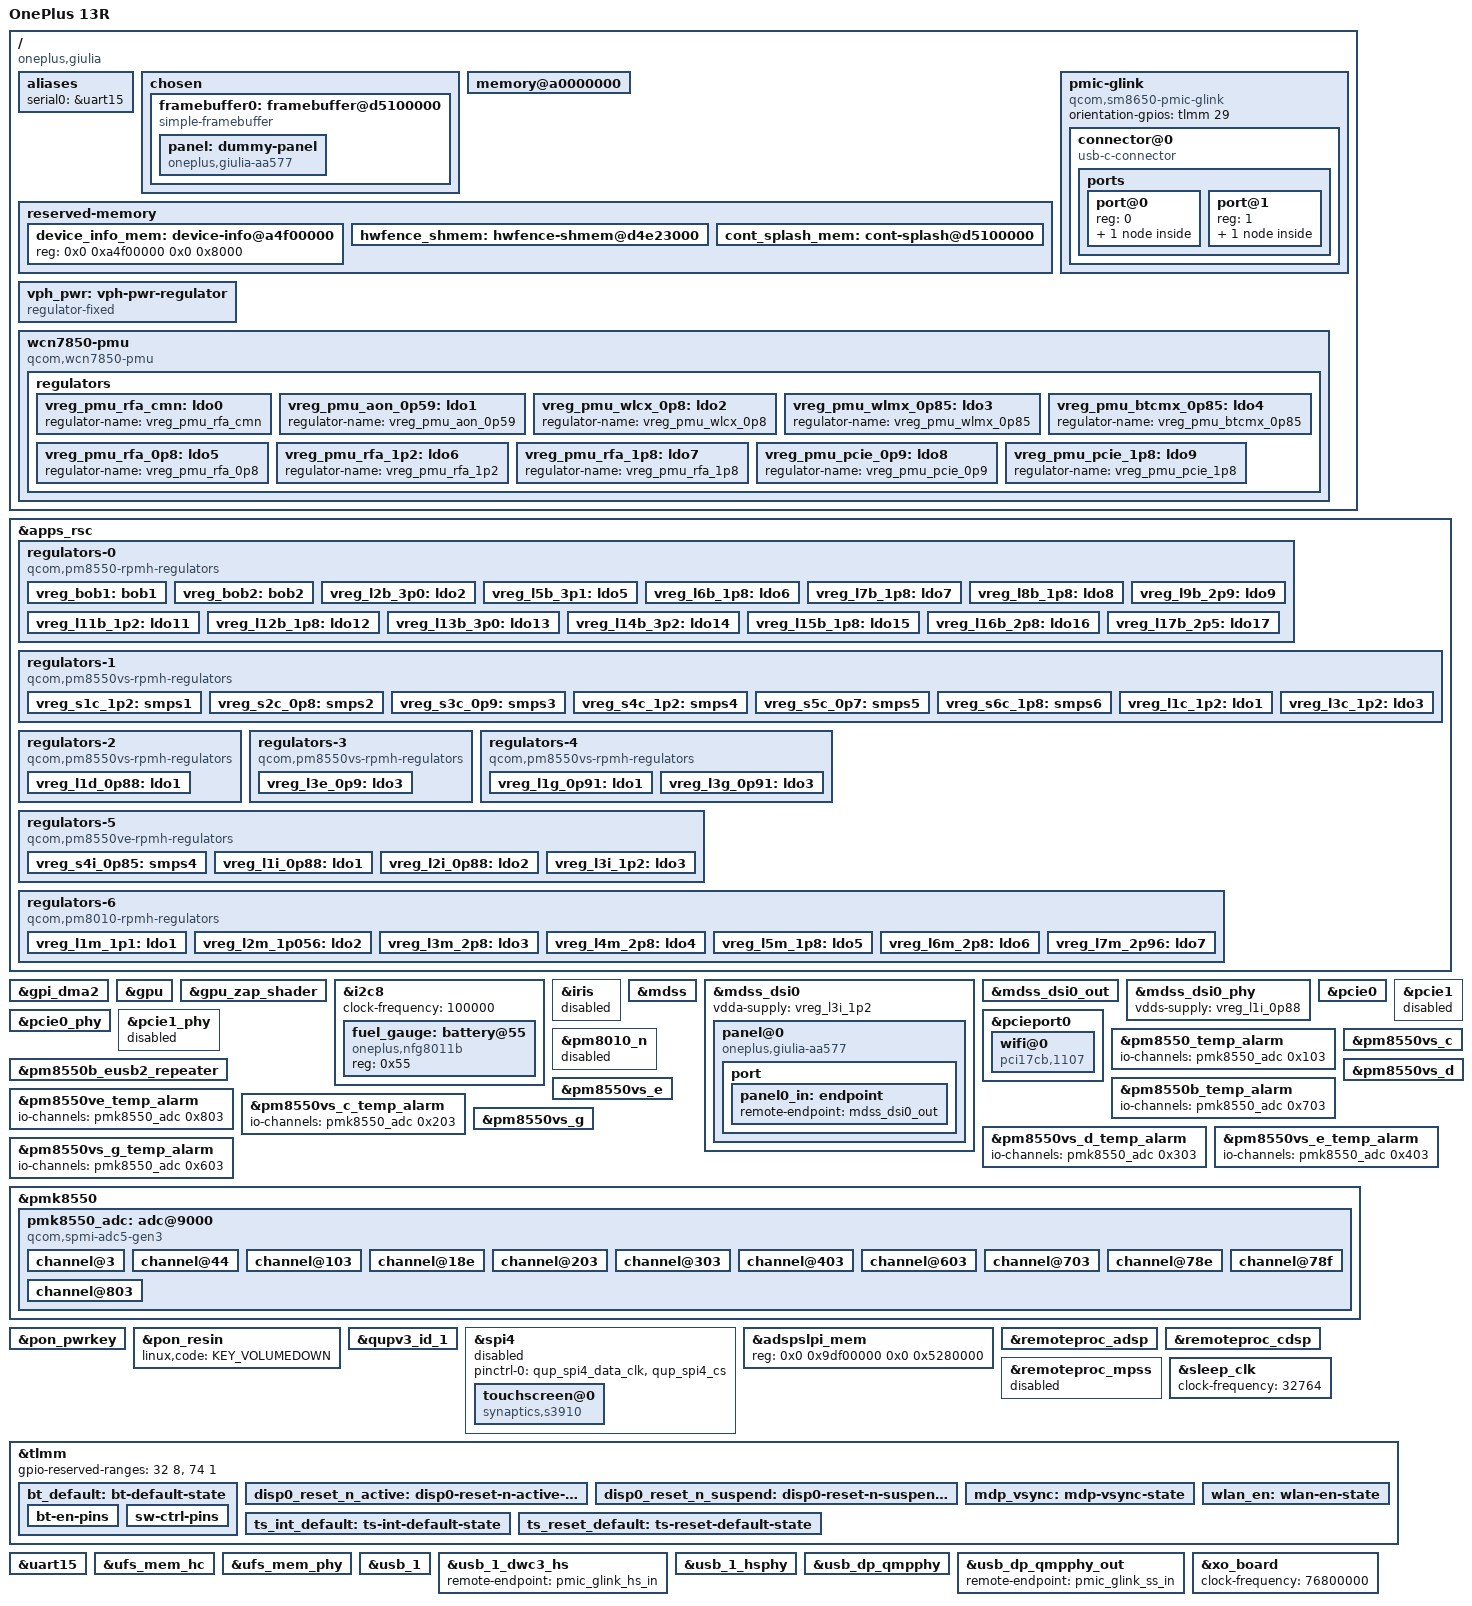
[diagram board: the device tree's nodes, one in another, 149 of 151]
// SPDX-License-Identifier: BSD-3-Clause
/*
 * Copyright (c) 2023, Linaro Limited
 * Copyright (c) 2026, OnePlus 13R (giulia) port
 *
 * OnePlus 13R / CPH2645 - codename "giulia", SM8650 (Pineapple v2, rev 2.0).
 *
 * Derived from sm8650-mtp.dts: this board's downstream compatible is
 * "qcom,pineapple-mtp", so the MTP reference design is its direct ancestor.
 * Display pinout and rails were verified identical to MTP against the
 * shipping firmware DTB (reset gpio133, TE gpio86, L11B/L12B/L13B).
 *
 * Board data extracted from dtbo overlay 02.dtb of firmware
 * CPH2645_11.C.66_1660_202510060015 (OOS 15.0.0.871), whose source is
 * LineageOS devicetrees oplus/giulia-23867-pineapple-overlay.dts.
 *
 * 02.dtb is the overlay ABL applies on this handset - production
 * hardware, project 23867, rev 2.0.
 */

/dts-v1/;

#include <dt-bindings/regulator/qcom,rpmh-regulator.h>
#include "sm8650.dtsi"
#include "pm8010.dtsi"
#include "pm8550.dtsi"
#include "pm8550b.dtsi"
#define PMK8550VE_SID 8
#include "pm8550ve.dtsi"
#include "pm8550vs.dtsi"
#include "pmk8550.dtsi"
#include "pmr735d_a.dtsi"

/ {
	model = "OnePlus 13R";
	compatible = "oneplus,giulia", "qcom,sm8650";

	/*
	 * NOT mainline properties - Linux ignores both. They exist for the
	 * Android bootloader (ABL), which matches an appended DTB on these
	 * before it will boot it, and which may reject a tree carrying
	 * neither. DROP BOTH BEFORE SUBMITTING UPSTREAM.
	 *
	 * VERIFIED ON THIS DEVICE - read as root from the live
	 * tree ABL produced:
	 *   /proc/device-tree/qcom,msm-id   0000022d 00020000 00000241 00020000
	 *   /proc/device-tree/qcom,board-id 00000008 00000000
	 * Byte-for-byte what is written below. 0x22d = 557 = SM8650,
	 * 0x20000 = SoC rev 2.0, matching the rev that picks 05.dtb.
	 */
	qcom,msm-id = <0x22d 0x20000>, <0x241 0x20000>;

	/*
	 * qcom,board-id DELIBERATELY OMITTED.
	 *
	 * <0x08 0x00> matches ALL TEN downstream dtbo overlays, so ABL will
	 * fdt_overlay one of them onto this mainline tree. Their fixups
	 * reference labels that do not exist here, so application fails inside
	 * ABL - before the kernel is ever entered. Without it no overlay
	 * matches and ABL should hand over the base tree untouched.
	 *
	 * msm-id is kept: ABL selects the base DTB on that.
	 *
	 *   qcom,board-id = <0x08 0x00>;
	 */

	chassis-type = "handset";

	aliases {
		serial0 = &uart15;
	};

	chosen {
		#address-cells = <2>;
		#size-cells = <2>;
		ranges;

		stdout-path = "serial0:115200n8";

		/*
		 * This string and `CONFIG_CMDLINE` must stay byte-identical.
		 */
		bootargs = "console=tty0 console=ttyGS0 console=ttyMSM0,115200n8 clk_ignore_unused pd_ignore_unused regulator_ignore_unused initcall_blacklist=simpledrm_platform_driver_init loglevel=5 panic=0";

		/*
		 * Framebuffer inherited from the bootloader splash. Gives
		 * visible output before any DSI driver exists.
		 *
		 * Address, size, resolution and depth corroborated against
		 * Mu-Silicium's giulia UEFI port, which reuses this same
		 * XBL framebuffer and has it working on this hardware:
		 *   Platforms/OnePlus/giuliaPkg/giulia.dsc:70-72
		 *     PcdFrameBufferWidth|1264 Height|2780 ColorDepth|32
		 *   .../giuliaPkg/Library/MemoryMapLib/MemoryMapLib.c:31
		 *     {"Display_Reserved", 0xD5100000, 0x02B00000, ...}
		 *
		 * Format follows from the same source: at ColorDepth 32 its
		 * SimpleFbDxe sets PixelBlueGreenRedReserved8BitPerColor
		 * (SimpleFb.c:182) - B,G,R,reserved byte order, i.e. a
		 * 0x00RRGGBB LE word = x8r8g8b8. Byte 3 is *reserved*, not
		 * alpha.
		 */
		framebuffer0: framebuffer@d5100000 {
			compatible = "simple-framebuffer";
			reg = <0x0 0xd5100000 0x0 (1264 * 2780 * 4)>;
			width = <1264>;
			height = <2780>;
			stride = <(1264 * 4)>;
			format = "x8r8g8b8";
			panel = <&panel>;

			/*
			 * These hold the display path up so the bootloader
			 * framebuffer survives; without them the clocks get
			 * gated and the image dies early in boot.
			 */
			interconnects = <&mmss_noc MASTER_MDP QCOM_ICC_TAG_ALWAYS
					 &mc_virt SLAVE_EBI1 QCOM_ICC_TAG_ALWAYS>;
			clocks = <&gcc GCC_DISP_HF_AXI_CLK>;

			/* Dimension info only - not a real panel driver */
			panel: dummy-panel {
				compatible = "oneplus,giulia-aa577";
				width-mm = <71>;
				height-mm = <157>;
			};
		};
	};

	/*
	 * OVERRIDES sm8650.dtsi:719, which declares
	 *   reg = <0 0xa0000000 0 0>;   / * bootloader fills in the size * /
	 * That assumption is FALSE on this device. ABL patches the memory node of
	 * the downstream tree it ships, not ours - a mainline DTB boots with a
	 * zero-size memory node, i.e. the kernel is told it has no RAM at all and
	 * dies instantly, before earlycon or any framebuffer. Silent and total.
	 *
	 * Values are the live map read from /sys/firmware/fdt on this handset
	 * (giulia-runtime.dtb) - 13 usable banks, 11.23 GiB. One zero-size entry
	 * at 0xd8800000 present in the runtime tree is dropped.
	 */
	memory@a0000000 {
		device_type = "memory";
		reg = <0x0 0x816e0000 0x0 0x00320000>,
		      <0x0 0x81cf5000 0x0 0x0000b000>,
		      <0x0 0x81f20000 0x0 0x00580000>,
		      <0x0 0x82800000 0x0 0x02000000>,
		      <0x0 0x84a00000 0x0 0x02100000>,
		      <0x0 0xa3180000 0x0 0x31ca3000>,
		      <0x0 0xd5100000 0x0 0x02f00000>,
		      <0x0 0xe1bb0000 0x0 0x1dc50000>,
		      <0x0 0xffe00000 0x0 0x00200000>,
		      <0x8 0x80000000 0x0 0x2f900000>,
		      <0x8 0xb0000000 0x0 0x07f00000>,
		      <0x8 0xc0000000 0x0 0xc0000000>,
		      <0x9 0x80000000 0x1 0x80000000>;
	};

	reserved-memory {
		#address-cells = <2>;
		#size-cells = <2>;
		ranges;

		/*
		 * sm8650.dtsi already reserves 35 regions (hyp, smem, cmd-db,
		 * mpss, adsp/cdsp, tz, vm carve-outs) at addresses identical to
		 * this device's firmware tree. Only the giulia-specific deltas
		 * are added here.
		 */

		/*
		 * The one firmware carve-out the shipping
		 * tree reserves and this one did not, so the kernel was free to
		 * allocate it and eventually wrote to it. Declared exactly as
		 * downstream does - a plain reservation, no no-map.
		 */
		device_info_mem: device-info@a4f00000 {
			reg = <0x0 0xa4f00000 0x0 0x8000>;
		};

		hwfence_shmem: hwfence-shmem@d4e23000 {
			reg = <0x0 0xd4e23000 0x0 0x2dd000>;
			no-map;
		};

		/* Bootloader splash - backs framebuffer0 in /chosen */
		cont_splash_mem: cont-splash@d5100000 {
			reg = <0x0 0xd5100000 0x0 0x2b00000>;
			no-map;
		};
	};

	pmic-glink {
		compatible = "qcom,sm8650-pmic-glink",
			     "qcom,sm8550-pmic-glink",
			     "qcom,pmic-glink";
		#address-cells = <1>;
		#size-cells = <0>;
		orientation-gpios = <&tlmm 29 GPIO_ACTIVE_HIGH>;

		connector@0 {
			compatible = "usb-c-connector";
			reg = <0>;

			power-role = "dual";
			data-role = "dual";

			ports {
				#address-cells = <1>;
				#size-cells = <0>;

				port@0 {
					reg = <0>;

					pmic_glink_hs_in: endpoint {
						remote-endpoint = <&usb_1_dwc3_hs>;
					};
				};

				port@1 {
					reg = <1>;

					pmic_glink_ss_in: endpoint {
						remote-endpoint = <&usb_dp_qmpphy_out>;
					};
				};
			};
		};
	};

	/*
	 * MTP's sound node targets WSA8845 speakers; giulia
	 * has WSA884x plus a wcd939x codec and sia91xx amps. Needs its own
	 * node - deliberately omitted rather than carried over wrong.
	 */

	vph_pwr: vph-pwr-regulator {
		compatible = "regulator-fixed";

		regulator-name = "vph_pwr";
		regulator-min-microvolt = <3700000>;
		regulator-max-microvolt = <3700000>;

		regulator-always-on;
		regulator-boot-on;
	};

	/*
	 * WLAN/BT combo: WCN7850, on pcie0. Downstream calls it "cnss-kiwi" -
	 * kiwi is Qualcomm's codename for this part.
	 *
	 * Structure and every value below are sm8650-qrd.dts's: it is the phone
	 * reference for this SoC and carries the same combo. All seven input
	 * rails already exist on this board.
	 *
	 * This node powers the chip; the endpoint that consumes its LDOs is
	 * wifi@0 under &pcieport0. Both are required - pcie0 on its own brings
	 * up a link to a part that was never turned on.
	 *
	 * bt-enable-gpios is the one unverified number here. gpio16 for WLAN
	 * is confirmed (pin 16 is claimed by b0000000.qcom,cnss-kiwi in the
	 * snapshot); pin 17 reads "MUX UNCLAIMED / GPIO UNCLAIMED" there because
	 * Bluetooth was off when it was captured, so gpio17 is qrd's value
	 * carried over. BT is a separate UART path and is not enabled here.
	 */
	wcn7850-pmu {
		compatible = "qcom,wcn7850-pmu";

		pinctrl-names = "default";
		pinctrl-0 = <&wlan_en>, <&bt_default>;

		wlan-enable-gpios = <&tlmm 16 GPIO_ACTIVE_HIGH>;
		bt-enable-gpios = <&tlmm 17 GPIO_ACTIVE_HIGH>;

		vdd-supply = <&vreg_s4i_0p85>;
		vddio-supply = <&vreg_l15b_1p8>;
		vddio1p2-supply = <&vreg_l3c_1p2>;
		vddaon-supply = <&vreg_s2c_0p8>;
		vdddig-supply = <&vreg_s3c_0p9>;
		vddrfa1p2-supply = <&vreg_s1c_1p2>;
		vddrfa1p8-supply = <&vreg_s6c_1p8>;

		clocks = <&rpmhcc RPMH_RF_CLK1>;

		/*
		 * Downstream CNSS sends these AOP WLAN PDC defaults before it
		 * powers the WCN7850; pwrseq-qcom-wcn replays them from here.
		 */
		qcom,qmp = <&aoss_qmp>;
		qcom,pdc-init-table =
			"{class: wlan_pdc, ss: rf, res: s3c.v, upval: 916}",
			"{class: wlan_pdc, ss: rf, res: s3c.v, dwnval: 612}",
			"{class: wlan_pdc, ss: rf, res: s1c.v, upval: 1316}",
			"{class: wlan_pdc, ss: rf, res: s1c.v, dwnval: 944}",
			"{class: wlan_pdc, ss: rf, res: s6c.v, upval: 1864}",
			"{class: wlan_pdc, ss: rf, res: s6c.v, dwnval: 1820}",
			"{class: wlan_pdc, ss: bb, res: s2c.v, upval: 976}",
			"{class: wlan_pdc, ss: bb, res: s2c.v, dwnval: 512}",
			"{class: wlan_pdc, ss: bb, res: s4i.v, upval: 940}",
			"{class: wlan_pdc, ss: bb, res: s4i.v, dwnval: 420}";

		regulators {
			vreg_pmu_rfa_cmn: ldo0 {
				regulator-name = "vreg_pmu_rfa_cmn";
			};

			vreg_pmu_aon_0p59: ldo1 {
				regulator-name = "vreg_pmu_aon_0p59";
			};

			vreg_pmu_wlcx_0p8: ldo2 {
				regulator-name = "vreg_pmu_wlcx_0p8";
			};

			vreg_pmu_wlmx_0p85: ldo3 {
				regulator-name = "vreg_pmu_wlmx_0p85";
			};

			vreg_pmu_btcmx_0p85: ldo4 {
				regulator-name = "vreg_pmu_btcmx_0p85";
			};

			vreg_pmu_rfa_0p8: ldo5 {
				regulator-name = "vreg_pmu_rfa_0p8";
			};

			vreg_pmu_rfa_1p2: ldo6 {
				regulator-name = "vreg_pmu_rfa_1p2";
			};

			vreg_pmu_rfa_1p8: ldo7 {
				regulator-name = "vreg_pmu_rfa_1p8";
			};

			vreg_pmu_pcie_0p9: ldo8 {
				regulator-name = "vreg_pmu_pcie_0p9";
			};

			vreg_pmu_pcie_1p8: ldo9 {
				regulator-name = "vreg_pmu_pcie_1p8";
			};
		};
	};
};

&apps_rsc {
	regulators-0 {
		compatible = "qcom,pm8550-rpmh-regulators";

		vdd-bob1-supply = <&vph_pwr>;
		vdd-bob2-supply = <&vph_pwr>;
		vdd-l2-l13-l14-supply = <&vreg_bob1>;
		vdd-l3-supply = <&vreg_s1c_1p2>;
		vdd-l5-l16-supply = <&vreg_bob1>;
		vdd-l6-l7-supply = <&vreg_bob1>;
		vdd-l8-l9-supply = <&vreg_bob1>;
		vdd-l11-supply = <&vreg_s1c_1p2>;
		vdd-l12-supply = <&vreg_s6c_1p8>;
		vdd-l15-supply = <&vreg_s6c_1p8>;
		vdd-l17-supply = <&vreg_bob2>;

		qcom,pmic-id = "b";

		vreg_bob1: bob1 {
			regulator-name = "vreg_bob1";
			regulator-min-microvolt = <3296000>;
			regulator-max-microvolt = <3960000>;
			regulator-initial-mode = <RPMH_REGULATOR_MODE_HPM>;
		};

		vreg_bob2: bob2 {
			regulator-name = "vreg_bob2";
			regulator-min-microvolt = <2720000>;
			regulator-max-microvolt = <3008000>;
			regulator-initial-mode = <RPMH_REGULATOR_MODE_HPM>;
		};

		vreg_l2b_3p0: ldo2 {
			regulator-name = "vreg_l2b_3p0";
			regulator-min-microvolt = <3008000>;
			regulator-max-microvolt = <3008000>;
			regulator-initial-mode = <RPMH_REGULATOR_MODE_HPM>;
			regulator-allow-set-load;
			regulator-allowed-modes = <RPMH_REGULATOR_MODE_LPM
						   RPMH_REGULATOR_MODE_HPM>;
		};

		vreg_l5b_3p1: ldo5 {
			regulator-name = "vreg_l5b_3p1";
			regulator-min-microvolt = <3104000>;
			regulator-max-microvolt = <3104000>;
			regulator-initial-mode = <RPMH_REGULATOR_MODE_HPM>;
			regulator-allow-set-load;
			regulator-allowed-modes = <RPMH_REGULATOR_MODE_LPM
						   RPMH_REGULATOR_MODE_HPM>;
		};

		vreg_l6b_1p8: ldo6 {
			regulator-name = "vreg_l6b_1p8";
			regulator-min-microvolt = <1800000>;
			regulator-max-microvolt = <3008000>;
			regulator-initial-mode = <RPMH_REGULATOR_MODE_HPM>;
			regulator-allow-set-load;
			regulator-allowed-modes = <RPMH_REGULATOR_MODE_LPM
						   RPMH_REGULATOR_MODE_HPM>;
		};

		vreg_l7b_1p8: ldo7 {
			regulator-name = "vreg_l7b_1p8";
			regulator-min-microvolt = <1800000>;
			regulator-max-microvolt = <3008000>;
			regulator-initial-mode = <RPMH_REGULATOR_MODE_HPM>;
		};

		vreg_l8b_1p8: ldo8 {
			regulator-name = "vreg_l8b_1p8";
			regulator-min-microvolt = <1800000>;
			regulator-max-microvolt = <3008000>;
			regulator-initial-mode = <RPMH_REGULATOR_MODE_HPM>;
			regulator-allow-set-load;
			regulator-allowed-modes = <RPMH_REGULATOR_MODE_LPM
						   RPMH_REGULATOR_MODE_HPM>;
		};

		vreg_l9b_2p9: ldo9 {
			regulator-name = "vreg_l9b_2p9";
			regulator-min-microvolt = <2960000>;
			regulator-max-microvolt = <3008000>;
			regulator-initial-mode = <RPMH_REGULATOR_MODE_HPM>;
			regulator-allow-set-load;
			regulator-allowed-modes = <RPMH_REGULATOR_MODE_LPM
						   RPMH_REGULATOR_MODE_HPM>;
		};

		vreg_l11b_1p2: ldo11 {
			regulator-name = "vreg_l11b_1p2";
			regulator-min-microvolt = <1200000>;
			regulator-max-microvolt = <1504000>;
			regulator-initial-mode = <RPMH_REGULATOR_MODE_HPM>;
			regulator-allow-set-load;
			regulator-allowed-modes = <RPMH_REGULATOR_MODE_LPM
						   RPMH_REGULATOR_MODE_HPM>;
		};

		vreg_l12b_1p8: ldo12 {
			regulator-name = "vreg_l12b_1p8";
			regulator-min-microvolt = <1800000>;
			regulator-max-microvolt = <1800000>;
			regulator-initial-mode = <RPMH_REGULATOR_MODE_HPM>;
			regulator-allow-set-load;
			regulator-allowed-modes = <RPMH_REGULATOR_MODE_LPM
						   RPMH_REGULATOR_MODE_HPM>;
		};

		vreg_l13b_3p0: ldo13 {
			regulator-name = "vreg_l13b_3p0";
			regulator-min-microvolt = <3000000>;
			regulator-max-microvolt = <3000000>;
			regulator-initial-mode = <RPMH_REGULATOR_MODE_HPM>;
			regulator-allow-set-load;
			regulator-allowed-modes = <RPMH_REGULATOR_MODE_LPM
						   RPMH_REGULATOR_MODE_HPM>;
		};

		vreg_l14b_3p2: ldo14 {
			regulator-name = "vreg_l14b_3p2";
			regulator-min-microvolt = <3200000>;
			regulator-max-microvolt = <3200000>;
			regulator-initial-mode = <RPMH_REGULATOR_MODE_HPM>;
			regulator-allow-set-load;
			regulator-allowed-modes = <RPMH_REGULATOR_MODE_LPM
						   RPMH_REGULATOR_MODE_HPM>;
		};

		vreg_l15b_1p8: ldo15 {
			regulator-name = "vreg_l15b_1p8";
			regulator-min-microvolt = <1800000>;
			regulator-max-microvolt = <1800000>;
			regulator-initial-mode = <RPMH_REGULATOR_MODE_HPM>;
			regulator-allow-set-load;
			regulator-allowed-modes = <RPMH_REGULATOR_MODE_LPM
						   RPMH_REGULATOR_MODE_HPM>;
		};

		vreg_l16b_2p8: ldo16 {
			regulator-name = "vreg_l16b_2p8";
			regulator-min-microvolt = <2800000>;
			regulator-max-microvolt = <2800000>;
			regulator-initial-mode = <RPMH_REGULATOR_MODE_HPM>;
			regulator-allow-set-load;
			regulator-allowed-modes = <RPMH_REGULATOR_MODE_LPM
						   RPMH_REGULATOR_MODE_HPM>;
		};

		vreg_l17b_2p5: ldo17 {
			regulator-name = "vreg_l17b_2p5";
			regulator-min-microvolt = <2504000>;
			regulator-max-microvolt = <2504000>;
			regulator-initial-mode = <RPMH_REGULATOR_MODE_HPM>;
			regulator-allow-set-load;
			regulator-allowed-modes = <RPMH_REGULATOR_MODE_LPM
						   RPMH_REGULATOR_MODE_HPM>;
		};
	};

	regulators-1 {
		compatible = "qcom,pm8550vs-rpmh-regulators";

		vdd-l1-supply = <&vreg_s1c_1p2>;
		vdd-l2-supply = <&vreg_s1c_1p2>;
		vdd-l3-supply = <&vreg_s1c_1p2>;
		vdd-s1-supply = <&vph_pwr>;
		vdd-s2-supply = <&vph_pwr>;
		vdd-s3-supply = <&vph_pwr>;
		vdd-s4-supply = <&vph_pwr>;
		vdd-s5-supply = <&vph_pwr>;
		vdd-s6-supply = <&vph_pwr>;

		qcom,pmic-id = "c";

		vreg_s1c_1p2: smps1 {
			regulator-name = "vreg_s1c_1p2";
			regulator-min-microvolt = <1316000>;
			regulator-max-microvolt = <1348000>;
			regulator-initial-mode = <RPMH_REGULATOR_MODE_HPM>;
		};

		vreg_s2c_0p8: smps2 {
			regulator-name = "vreg_s2c_0p8";
			regulator-min-microvolt = <976000>;
			regulator-max-microvolt = <1036000>;
			regulator-initial-mode = <RPMH_REGULATOR_MODE_HPM>;
		};

		vreg_s3c_0p9: smps3 {
			regulator-name = "vreg_s3c_0p9";
			regulator-min-microvolt = <916000>;
			regulator-max-microvolt = <1064000>;
			regulator-initial-mode = <RPMH_REGULATOR_MODE_HPM>;
		};

		vreg_s4c_1p2: smps4 {
			regulator-name = "vreg_s4c_1p2";
			regulator-min-microvolt = <1224000>;
			regulator-max-microvolt = <1280000>;
			regulator-initial-mode = <RPMH_REGULATOR_MODE_HPM>;
		};

		vreg_s5c_0p7: smps5 {
			regulator-name = "vreg_s5c_0p7";
			regulator-min-microvolt = <752000>;
			regulator-max-microvolt = <900000>;
			regulator-initial-mode = <RPMH_REGULATOR_MODE_HPM>;
		};

		vreg_s6c_1p8: smps6 {
			regulator-name = "vreg_s6c_1p8";
			regulator-min-microvolt = <1864000>;
			regulator-max-microvolt = <2000000>;
			regulator-initial-mode = <RPMH_REGULATOR_MODE_HPM>;
		};

		vreg_l1c_1p2: ldo1 {
			regulator-name = "vreg_l1c_1p2";
			regulator-min-microvolt = <1200000>;
			regulator-max-microvolt = <1200000>;
			regulator-initial-mode = <RPMH_REGULATOR_MODE_HPM>;
			regulator-allow-set-load;
			regulator-allowed-modes = <RPMH_REGULATOR_MODE_LPM
						   RPMH_REGULATOR_MODE_HPM>;
		};

		vreg_l3c_1p2: ldo3 {
			regulator-name = "vreg_l3c_1p2";
			regulator-min-microvolt = <1200000>;
			regulator-max-microvolt = <1200000>;
			regulator-initial-mode = <RPMH_REGULATOR_MODE_HPM>;
			regulator-allow-set-load;
			regulator-allowed-modes = <RPMH_REGULATOR_MODE_LPM
						   RPMH_REGULATOR_MODE_HPM>;
		};
	};

	regulators-2 {
		compatible = "qcom,pm8550vs-rpmh-regulators";

		vdd-l1-supply = <&vreg_s3c_0p9>;

		qcom,pmic-id = "d";

		vreg_l1d_0p88: ldo1 {
			regulator-name = "vreg_l1d_0p88";
			regulator-min-microvolt = <912000>;
			regulator-max-microvolt = <920000>;
			regulator-initial-mode = <RPMH_REGULATOR_MODE_HPM>;
			regulator-allow-set-load;
			regulator-allowed-modes = <RPMH_REGULATOR_MODE_LPM
						   RPMH_REGULATOR_MODE_HPM>;
		};
	};

	regulators-3 {
		compatible = "qcom,pm8550vs-rpmh-regulators";

		vdd-l3-supply = <&vreg_s3c_0p9>;

		qcom,pmic-id = "e";

		vreg_l3e_0p9: ldo3 {
			regulator-name = "vreg_l3e_0p9";
			regulator-min-microvolt = <880000>;
			regulator-max-microvolt = <920000>;
			regulator-initial-mode = <RPMH_REGULATOR_MODE_HPM>;
			regulator-allow-set-load;
			regulator-allowed-modes = <RPMH_REGULATOR_MODE_LPM
						   RPMH_REGULATOR_MODE_HPM>;
		};
	};

	regulators-4 {
		compatible = "qcom,pm8550vs-rpmh-regulators";

		vdd-l1-supply = <&vreg_s3c_0p9>;
		vdd-l3-supply = <&vreg_s3c_0p9>;

		qcom,pmic-id = "g";

		vreg_l1g_0p91: ldo1 {
			regulator-name = "vreg_l1g_0p91";
			regulator-min-microvolt = <912000>;
			regulator-max-microvolt = <920000>;
			regulator-initial-mode = <RPMH_REGULATOR_MODE_HPM>;
			regulator-allow-set-load;
			regulator-allowed-modes = <RPMH_REGULATOR_MODE_LPM
						   RPMH_REGULATOR_MODE_HPM>;
		};

		vreg_l3g_0p91: ldo3 {
			regulator-name = "vreg_l3g_0p91";
			regulator-min-microvolt = <880000>;
			regulator-max-microvolt = <912000>;
			regulator-initial-mode = <RPMH_REGULATOR_MODE_HPM>;
			regulator-allow-set-load;
			regulator-allowed-modes = <RPMH_REGULATOR_MODE_LPM
						   RPMH_REGULATOR_MODE_HPM>;
		};
	};

	regulators-5 {
		compatible = "qcom,pm8550ve-rpmh-regulators";

		vdd-l1-supply = <&vreg_s3c_0p9>;
		vdd-l2-supply = <&vreg_s3c_0p9>;
		vdd-l3-supply = <&vreg_s1c_1p2>;
		vdd-s4-supply = <&vph_pwr>;

		qcom,pmic-id = "i";

		vreg_s4i_0p85: smps4 {
			regulator-name = "vreg_s4i_0p85";
			regulator-min-microvolt = <940000>;
			regulator-max-microvolt = <1004000>;
			regulator-initial-mode = <RPMH_REGULATOR_MODE_HPM>;
		};

		vreg_l1i_0p88: ldo1 {
			regulator-name = "vreg_l1i_0p88";
			regulator-min-microvolt = <880000>;
			regulator-max-microvolt = <912000>;
			regulator-initial-mode = <RPMH_REGULATOR_MODE_HPM>;
			regulator-allow-set-load;
			regulator-allowed-modes = <RPMH_REGULATOR_MODE_LPM
						   RPMH_REGULATOR_MODE_HPM>;
		};

		vreg_l2i_0p88: ldo2 {
			regulator-name = "vreg_l2i_0p88";
			regulator-min-microvolt = <880000>;
			regulator-max-microvolt = <912000>;
			regulator-initial-mode = <RPMH_REGULATOR_MODE_HPM>;
			regulator-allow-set-load;
			regulator-allowed-modes = <RPMH_REGULATOR_MODE_LPM
						   RPMH_REGULATOR_MODE_HPM>;
		};

		vreg_l3i_1p2: ldo3 {
			regulator-name = "vreg_l3i_0p91";
			regulator-min-microvolt = <1200000>;
			regulator-max-microvolt = <1200000>;
			regulator-initial-mode = <RPMH_REGULATOR_MODE_HPM>;
			regulator-allow-set-load;
			regulator-allowed-modes = <RPMH_REGULATOR_MODE_LPM
						   RPMH_REGULATOR_MODE_HPM>;
		};
	};

	regulators-6 {
		compatible = "qcom,pm8010-rpmh-regulators";
		qcom,pmic-id = "m";

		vdd-l1-l2-supply = <&vreg_s1c_1p2>;
		vdd-l3-l4-supply = <&vreg_bob2>;
		vdd-l5-supply = <&vreg_s6c_1p8>;
		vdd-l6-supply = <&vreg_bob1>;
		vdd-l7-supply = <&vreg_bob1>;

		vreg_l1m_1p1: ldo1 {
			regulator-name = "vreg_l1m_1p1";
			regulator-min-microvolt = <1104000>;
			regulator-max-microvolt = <1104000>;
			regulator-initial-mode = <RPMH_REGULATOR_MODE_HPM>;
			regulator-allow-set-load;
			regulator-allowed-modes = <RPMH_REGULATOR_MODE_LPM
						   RPMH_REGULATOR_MODE_HPM>;
		};

		vreg_l2m_1p056: ldo2 {
			regulator-name = "vreg_l2m_1p056";
			regulator-min-microvolt = <1056000>;
			regulator-max-microvolt = <1056000>;
			regulator-initial-mode = <RPMH_REGULATOR_MODE_HPM>;
			regulator-allow-set-load;
			regulator-allowed-modes = <RPMH_REGULATOR_MODE_LPM
						   RPMH_REGULATOR_MODE_HPM>;
		};

		vreg_l3m_2p8: ldo3 {
			regulator-name = "vreg_l3m_2p8";
			regulator-min-microvolt = <2800000>;
			regulator-max-microvolt = <2800000>;
			regulator-initial-mode = <RPMH_REGULATOR_MODE_HPM>;
		};

		vreg_l4m_2p8: ldo4 {
			regulator-name = "vreg_l4m_2p8";
			regulator-min-microvolt = <2800000>;
			regulator-max-microvolt = <2800000>;
			regulator-initial-mode = <RPMH_REGULATOR_MODE_HPM>;
		};

		vreg_l5m_1p8: ldo5 {
			regulator-name = "vreg_l5m_1p8";
			regulator-min-microvolt = <1800000>;
			regulator-max-microvolt = <1800000>;
			regulator-initial-mode = <RPMH_REGULATOR_MODE_HPM>;
		};

		vreg_l6m_2p8: ldo6 {
			regulator-name = "vreg_l6m_2p8";
			regulator-min-microvolt = <2800000>;
			regulator-max-microvolt = <2800000>;
			regulator-initial-mode = <RPMH_REGULATOR_MODE_HPM>;
		};

		vreg_l7m_2p96: ldo7 {
			regulator-name = "vreg_l7m_2p96";
			regulator-min-microvolt = <2960000>;
			regulator-max-microvolt = <2960000>;
			regulator-initial-mode = <RPMH_REGULATOR_MODE_HPM>;
		};
	};

	/*
	 * No regulators-7. pm8010n (RPMh pmic-id "n") is NOT populated on this
	 * board - it is MTP boilerplate, inherited the same way the
	 * dsi_vtdr6130_* nodes are. Settled from three independent
	 * sources: cmd_db publishes no ldon1..ldon7 resource (mainline queries
	 * "ldo%s%d" and gets nothing, while ldom1..7 on pm8010m all resolve);
	 * SPMI USID 0x0d never answers, though 0x0c does; and in the shipping
	 * devicetree pm8010m's rails have 39 consumers while pm8010n's have one,
	 * a disabled i3c-master@880000. Declaring it only buys a probe failure
	 * every boot. If a camera sensor ever asks for an "n" rail, that means
	 * the rail comes from somewhere else here - do not restore this block
	 * from sm8650-mtp.dts.
	 */
};

/*
 * GPI DMA for the QUP2 wrapper, which is i2c8's. Enabled together with the bus
 * because every sm8650 board upstream does it that way - hdk and qrd enable
 * gpi_dma1 alongside their i2c buses, and ayaneo enables gpi_dma2 specifically.
 *
 * Not decorative. `i2c-qcom-geni.c` reads GENI_IF_DISABLE_RO at probe: if the
 * SE's FIFO is fused off, GPI DMA is the *only* mode and `setup_gpi_dma()`
 * failing takes the bus down. FIFO is expected to be available here, so this is
 * belt-and-braces - but it costs one line and the alternative costs a boot.
 */
&gpi_dma2 {
	status = "okay";
};

&gpu {
	status = "okay";
};

&gpu_zap_shader {
	firmware-name = "qcom/sm8650/oneplus/giulia/gen70900_zap.mbn";
};

/*
 * i2c8 to reach the fuel gauge at 0x55.
 *
 * The battery values from `pmic-glink` are firmware placeholders because the
 * real gauge is not on the ADSP's path; it is here, on the applications
 * processor. `qupv3_id_1` is already enabled
 * below for the touch SPI, so this is only the bus.
 *
 * 100 kHz matches the vendor tree (`qcom,clk-freq-out = <0x186a0>`), which is
 * also the geni driver's default.
 */
&i2c8 {
	clock-frequency = <100000>;

	status = "okay";

	/*
	 * An NFG8011B, not the bq27541 the vendor node claims — it answers
	 * device type 0x4231 and leaves NAC/CYCT unpopulated.
	 */
	fuel_gauge: battery@55 {
		compatible = "oneplus,nfg8011b";
		reg = <0x55>;
	};
};

/* stage 2: video decode */
&iris {
	status = "disabled";
};

&mdss {
	status = "okay";
};

&mdss_dsi0 {
	vdda-supply = <&vreg_l3i_1p2>;

	status = "okay";

	panel@0 {
		compatible = "oneplus,giulia-aa577";
		reg = <0>;

		reset-gpios = <&tlmm 133 GPIO_ACTIVE_LOW>;

		vddio-supply = <&vreg_l12b_1p8>;
		vci-supply = <&vreg_l13b_3p0>;
		vdd-supply = <&vreg_l11b_1p2>;

		pinctrl-0 = <&disp0_reset_n_active>, <&mdp_vsync>;
		pinctrl-1 = <&disp0_reset_n_suspend>, <&mdp_vsync>;
		pinctrl-names = "default", "sleep";

		port {
			panel0_in: endpoint {
				remote-endpoint = <&mdss_dsi0_out>;
			};
		};
	};
};

&mdss_dsi0_out {
	remote-endpoint = <&panel0_in>;
	data-lanes = <0 1 2 3>;
};

&mdss_dsi0_phy {
	vdds-supply = <&vreg_l1i_0p88>;

	status = "okay";
};

/*
 * PCIe. pcie0 carries the WCN7850 WLAN - see the wcn7850-pmu node, which has
 * to be present or the endpoint below never powers on.
 *
 * These GPIOs are verified against the handset:
 * backups/android-snapshot/pinmux-pins has 94 and 96 claimed by
 * 1c00000.qcom,pcie with 95 muxed as pcie0_clk_req_n, and proc-interrupts
 * carries msm_pcie_wake on msmgpio 96. They agree with MTP and qrd.
 */
&pcie0 {
	wake-gpios = <&tlmm 96 GPIO_ACTIVE_HIGH>;
	perst-gpios = <&tlmm 94 GPIO_ACTIVE_LOW>;

	pinctrl-0 = <&pcie0_default_state>;
	pinctrl-names = "default";

	status = "okay";
};

&pcie0_phy {
	vdda-phy-supply = <&vreg_l1i_0p88>;
	vdda-pll-supply = <&vreg_l3i_1p2>;

	status = "okay";
};

&pcie1 {
	wake-gpios = <&tlmm 99 GPIO_ACTIVE_HIGH>;
	perst-gpios = <&tlmm 97 GPIO_ACTIVE_LOW>;

	pinctrl-0 = <&pcie1_default_state>;
	pinctrl-names = "default";

	status = "disabled";
};

&pcie1_phy {
	vdda-phy-supply = <&vreg_l3e_0p9>;
	vdda-pll-supply = <&vreg_l3i_1p2>;
	vdda-qref-supply = <&vreg_l1i_0p88>;

	status = "disabled";
};

/*
 * The WCN7850's WLAN endpoint. Its supplies are the PMU's own LDOs, so this
 * node is what makes the chip usable rather than merely powered.
 *
 * ath12k still has to find a board file matching this unit's board ID in
 * qcom/ath12k/WCN7850/hw2.0/board-2.bin, whose entries are mostly laptops.
 * If it misses, the failure names the exact lookup string it wanted.
 */
&pcieport0 {
	wifi@0 {
		compatible = "pci17cb,1107";
		reg = <0x10000 0x0 0x0 0x0 0x0>;

		vddrfacmn-supply = <&vreg_pmu_rfa_cmn>;
		vddaon-supply = <&vreg_pmu_aon_0p59>;
		vddwlcx-supply = <&vreg_pmu_wlcx_0p8>;
		vddwlmx-supply = <&vreg_pmu_wlmx_0p85>;
		vddrfa0p8-supply = <&vreg_pmu_rfa_0p8>;
		vddrfa1p2-supply = <&vreg_pmu_rfa_1p2>;
		vddrfa1p8-supply = <&vreg_pmu_rfa_1p8>;
		vddpcie0p9-supply = <&vreg_pmu_pcie_0p9>;
		vddpcie1p8-supply = <&vreg_pmu_pcie_1p8>;
	};
};

/*
 * pm8010.dtsi declares both pm8010_m@c and pm8010_n@d, but only the "m" part
 * exists on this board - see the regulators-6/7 comment in &apps_rsc. Leaving
 * "n" enabled costs an SPMI probe failure ("0-0d: transaction failed") every
 * boot, on a bus we do want quiet while USB and the PMICs are being brought up.
 */
&pm8010_n {
	status = "disabled";
};

/*
 * The seven temp-alarm nodes that can be made real, wired to their die-temp
 * ADC channel. Without io-channels these zones report a hardcoded 37000
 * forever - see the &pmk8550_adc comment below.
 */
&pm8550_temp_alarm {
	io-channels = <&pmk8550_adc 0x103>;
	io-channel-names = "thermal";
};

&pm8550b_eusb2_repeater {
	vdd18-supply = <&vreg_l15b_1p8>;
	vdd3-supply = <&vreg_l5b_3p1>;
};

&pm8550b_temp_alarm {
	io-channels = <&pmk8550_adc 0x703>;
	io-channel-names = "thermal";
};

&pm8550ve_temp_alarm {
	io-channels = <&pmk8550_adc 0x803>;
	io-channel-names = "thermal";
};

&pm8550vs_c {
	status = "okay";
};

&pm8550vs_c_temp_alarm {
	io-channels = <&pmk8550_adc 0x203>;
	io-channel-names = "thermal";
};

&pm8550vs_d {
	status = "okay";
};

&pm8550vs_d_temp_alarm {
	io-channels = <&pmk8550_adc 0x303>;
	io-channel-names = "thermal";
};

&pm8550vs_e {
	status = "okay";
};

&pm8550vs_e_temp_alarm {
	io-channels = <&pmk8550_adc 0x403>;
	io-channel-names = "thermal";
};

&pm8550vs_g {
	status = "okay";
};

&pm8550vs_g_temp_alarm {
	io-channels = <&pmk8550_adc 0x603>;
	io-channel-names = "thermal";
};

/*
 * The PMIC ADC. pmk8550.dtsi describes no ADC node at all,
 * so this one is transcribed from the runtime tree (giulia-runtime.dts,
 * vadc@9000): reg, interrupts and every channel's reg / label / pre-scaling
 * are the shipping firmware's own values.
 *
 * One node serves all eight PMICs. The ADC is implemented on SDAM peripherals
 * on the master PMIC (pmk8550, SID 0) rather than on a per-PMIC peripheral,
 * and the driver reaches the other dies by writing the SID register before
 * each conversion - so a channel's "reg" is a *virtual* channel number,
 * sid << 8 | channel.
 *
 * What it buys: real PMIC die temperatures. Every qcom,spmi-temp-alarm zone
 * reports a hardcoded 37000 without it, because qcom-spmi-temp-alarm.c
 * refreshes its cached value only when the over-temperature *stage* changes,
 * which at a normal die temperature never happens (hardware.md).
 *
 * Four channels the shipping tree declares are deliberately absent:
 * mainline's channel table has no entry for 0x718 (pm8550b_lite_die_temp),
 * 0x710 (chg_temp), 0x717 (iin_fb) or 0x7a1 (ichg_fb), and an unknown
 * channel fails probe for the *whole* device, not just that channel.
 *
 * qcom,adc-tm is deliberately not set on any channel. It is mainline's
 * spelling of downstream's qcom,adc-tm-type, and asking for it makes the
 * driver spawn an "adc5_tm_gen3" auxiliary device that mainline 7.2-rc6 has
 * no driver for. Threshold monitoring is unavailable either way; not asking
 * keeps an unbound device off the aux bus.
 *
 * The board thermistors (msm / cam_flash / wlan / pa / tof / gpio / usb /
 * subboard) are left for later. They are ordinary 100k-pull-up channels the
 * driver already understands, and reference readings for all of them are in
 * backups/android-snapshot/iio-channels - but three of them (wls_therm,
 * usb_temp_adc_l/r) carry a downstream qcom,scale-fn-type that mainline has
 * no DT property for, and two more duplicate a channel already named here.
 */
&pmk8550 {
	pmk8550_adc: adc@9000 {
		compatible = "qcom,spmi-adc5-gen3";
		reg = <0x9000>, <0x9100>;

		interrupts = <0x0 0x90 0x1 IRQ_TYPE_EDGE_RISING>,
			     <0x0 0x91 0x1 IRQ_TYPE_EDGE_RISING>;

		#address-cells = <1>;
		#size-cells = <0>;
		#io-channel-cells = <1>;

		/* PMK8550 (SID 0) */
		channel@3 {
			reg = <0x3>;
			label = "pmk8550_die_temp";
			qcom,pre-scaling = <1 1>;
		};

		channel@44 {
			reg = <0x44>;
			label = "pmk8550_xo_therm";
			qcom,ratiometric;
			qcom,hw-settle-time = <200>;
			qcom,pre-scaling = <1 1>;
		};

		/* PM8550 (SID 1) */
		channel@103 {
			reg = <0x103>;
			label = "pm8550_die_temp";
			qcom,pre-scaling = <1 1>;
		};

		channel@18e {
			reg = <0x18e>;
			label = "pm8550_vph_pwr";
			qcom,pre-scaling = <1 3>;
		};

		/* PM8550VS_C (SID 2) */
		channel@203 {
			reg = <0x203>;
			label = "pm8550vs_c_die_temp";
			qcom,pre-scaling = <1 1>;
		};

		/* PM8550VS_D (SID 3) */
		channel@303 {
			reg = <0x303>;
			label = "pm8550vs_d_die_temp";
			qcom,pre-scaling = <1 1>;
		};

		/* PM8550VS_E (SID 4) */
		channel@403 {
			reg = <0x403>;
			label = "pm8550vs_e_die_temp";
			qcom,pre-scaling = <1 1>;
		};

		/* PM8550VS_G (SID 6) */
		channel@603 {
			reg = <0x603>;
			label = "pm8550vs_g_die_temp";
			qcom,pre-scaling = <1 1>;
		};

		/* PM8550B (SID 7) */
		channel@703 {
			reg = <0x703>;
			label = "pm8550b_die_temp";
			qcom,pre-scaling = <1 1>;
		};

		channel@78e {
			reg = <0x78e>;
			label = "pm8550b_vph_pwr";
			qcom,pre-scaling = <1 3>;
		};

		/*
		 * The PMIC's own battery sense.
		 */
		channel@78f {
			reg = <0x78f>;
			label = "pm8550b_vbat_sns_qbg";
			qcom,pre-scaling = <1 3>;
		};

		/* PM8550VE (SID 8) */
		channel@803 {
			reg = <0x803>;
			label = "pm8550ve_die_temp";
			qcom,pre-scaling = <1 1>;
		};
	};
};

/*
 * Power and volume-down keys.
 *
 * Two things are needed together and neither is enough alone:
 * CONFIG_POWER_RESET_QCOM_PON=y (it was =m, so pon@1300 never bound and these
 * children were never populated), and these two status = "okay" overrides,
 * because pmk8550.dtsi ships both disabled for board files to enable.
 * Idiom taken from sm8650-hdk.dts:1065.
 */
&pon_pwrkey {
	status = "okay";
};

&pon_resin {
	linux,code = <KEY_VOLUMEDOWN>;

	status = "okay";
};

&qupv3_id_1 {
	status = "okay";
};

/*
 * touchscreen. Synaptics S3910 on spi@a90000 (spi4), confirmed
 * fitted on this unit via /sys/bus/spi/devices/spi0.0/driver ->
 * synaptics_tcm_spi.
 *
 * No mainline driver exists for the Synaptics TCM HBP protocol. Downstream
 * source: modules/oplus/kernel/tp/hbp/hbp/chips/synaptics/s3910/.
 */
&spi4 {
	pinctrl-0 = <&qup_spi4_data_clk>, <&qup_spi4_cs>;
	pinctrl-names = "default";

	status = "disabled";

	touchscreen@0 {
		compatible = "synaptics,s3910";
		reg = <0>;

		spi-max-frequency = <19000000>;

		interrupt-parent = <&tlmm>;
		interrupts = <162 IRQ_TYPE_LEVEL_LOW>;

		reset-gpios = <&tlmm 161 GPIO_ACTIVE_LOW>;

		/*
		 * Downstream supplies vdd from pm8550 L4B. No mainline sm8650
		 * board defines ldo4 on this PMIC, and its parent rail
		 * (vdd-l4-supply) is unverified - add the regulator to
		 * regulators-0 before wiring this up.
		 */

		pinctrl-0 = <&ts_int_default>, <&ts_reset_default>;
		pinctrl-names = "default";
	};
};

&adspslpi_mem {
	reg = <0x0 0x9df00000 0x0 0x5280000>;
};

/*
 * Remoteprocs
 *
 * ADSP is the interesting one: pmic-glink and PDR both wait on it, so Type-C
 * role switching and battery management stay out of reach until it runs.
 */
&remoteproc_adsp {
	firmware-name = "qcom/sm8650/oneplus/giulia/adsp.mbn",
			"qcom/sm8650/oneplus/giulia/adsp_dtb.mbn";

	status = "okay";
};

&remoteproc_cdsp {
	firmware-name = "qcom/sm8650/oneplus/giulia/cdsp.mbn",
			"qcom/sm8650/oneplus/giulia/cdsp_dtb.mbn";

	status = "okay";
};

&remoteproc_mpss {
	firmware-name = "qcom/sm8650/oneplus/giulia/modem.mbn",
			"qcom/sm8650/oneplus/giulia/modem_dtb.mbn";

	status = "disabled";
};

&sleep_clk {
	clock-frequency = <32764>;
};

/*
 * SoundWire speakers. giulia has WSA884x
 */

&tlmm {
	/* Reserved I/Os for NFC */
	gpio-reserved-ranges = <32 8>, <74 1>;

	/* WCN7850 BT enable + SW_CTRL, from qrd - see the wcn7850-pmu node */
	bt_default: bt-default-state {
		bt-en-pins {
			pins = "gpio17";
			function = "gpio";
			drive-strength = <16>;
			bias-disable;
		};

		sw-ctrl-pins {
			pins = "gpio18";
			function = "gpio";
			bias-pull-down;
		};
	};

	disp0_reset_n_active: disp0-reset-n-active-state {
		pins = "gpio133";
		function = "gpio";
		drive-strength = <8>;
		bias-disable;
	};

	disp0_reset_n_suspend: disp0-reset-n-suspend-state {
		pins = "gpio133";
		function = "gpio";
		drive-strength = <2>;
		bias-pull-down;
	};

	mdp_vsync: mdp-vsync-state {
		pins = "gpio86";
		function = "mdp_vsync";
		drive-strength = <2>;
		bias-pull-down;
	};

	/* Synaptics S3910 touchscreen */
	ts_int_default: ts-int-default-state {
		pins = "gpio162";
		function = "gpio";
		drive-strength = <2>;
		bias-pull-up;
		input-enable;
	};

	ts_reset_default: ts-reset-default-state {
		pins = "gpio161";
		function = "gpio";
		drive-strength = <2>;
		bias-disable;
		output-high;
	};

	/* WCN7850 WLAN enable - gpio16 confirmed against the Android snapshot */
	wlan_en: wlan-en-state {
		pins = "gpio16";
		function = "gpio";
		drive-strength = <8>;
		bias-pull-down;
	};
};

&uart15 {
	status = "okay";
};

&ufs_mem_hc {
	reset-gpios = <&tlmm 210 GPIO_ACTIVE_LOW>;

	vcc-supply = <&vreg_l17b_2p5>;
	vcc-max-microamp = <1300000>;
	vccq-supply = <&vreg_l1c_1p2>;
	vccq-max-microamp = <1200000>;

	status = "okay";
};

&ufs_mem_phy {
	vdda-phy-supply = <&vreg_l1d_0p88>;
	vdda-pll-supply = <&vreg_l3i_1p2>;

	status = "okay";
};

&usb_1 {
	dr_mode = "otg";
	usb-role-switch;

	status = "okay";
};

&usb_1_dwc3_hs {
	remote-endpoint = <&pmic_glink_hs_in>;
};

&usb_1_hsphy {
	vdd-supply = <&vreg_l1i_0p88>;
	vdda12-supply = <&vreg_l3i_1p2>;

	phys = <&pm8550b_eusb2_repeater>;

	status = "okay";
};

&usb_dp_qmpphy {
	vdda-phy-supply = <&vreg_l3i_1p2>;
	vdda-pll-supply = <&vreg_l3g_0p91>;

	status = "okay";
};

&usb_dp_qmpphy_out {
	remote-endpoint = <&pmic_glink_ss_in>;
};

&xo_board {
	clock-frequency = <76800000>;
};
